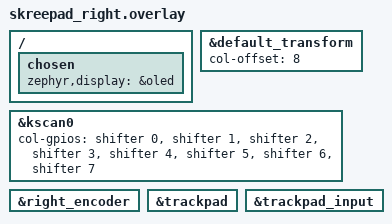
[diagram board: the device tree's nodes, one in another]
#include "skreepad.dtsi"

/ {
    chosen {
        zephyr,display = &oled;
    };
};

&default_transform {
    col-offset = <8>;
};

&kscan0 {
    col-gpios
        = <&shifter 0 GPIO_ACTIVE_HIGH>
        , <&shifter 1 GPIO_ACTIVE_HIGH>
        , <&shifter 2 GPIO_ACTIVE_HIGH>
        , <&shifter 3 GPIO_ACTIVE_HIGH>
        , <&shifter 4 GPIO_ACTIVE_HIGH>
        , <&shifter 5 GPIO_ACTIVE_HIGH>
        , <&shifter 6 GPIO_ACTIVE_HIGH>
        , <&shifter 7 GPIO_ACTIVE_HIGH>
        ;
};

&right_encoder {
    status = "okay";
};

&trackpad {
    status = "okay";
};

&trackpad_input {
    status = "okay";
};
